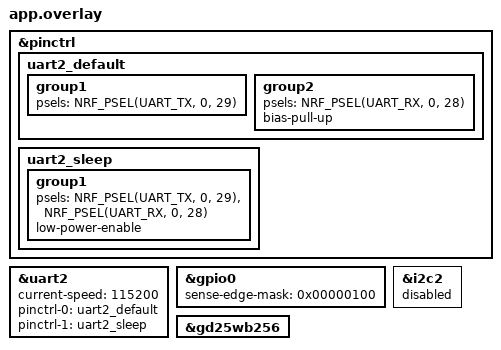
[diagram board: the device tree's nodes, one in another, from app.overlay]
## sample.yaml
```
# Copyright (c) 2026 Nordic Semiconductor ASA
# SPDX-License-Identifier: LicenseRef-Nordic-5-Clause


sample:
  name: nRF Cloud MQTT Device message
tests:
  sample.cellular.nrf_cloud_mqtt_device_message:
    sysbuild: true
    build_only: true
    integration_platforms:
      - nrf9151dk/nrf9151/ns
      - nrf9160dk/nrf9160/ns
      - nrf9161dk/nrf9161/ns
      - thingy91x/nrf9151/ns
    platform_allow:
      - nrf9151dk/nrf9151/ns
      - nrf9160dk/nrf9160/ns
      - nrf9161dk/nrf9161/ns
      - thingy91x/nrf9151/ns
    tags:
      - ci_build
      - sysbuild
      - ci_samples_cellular
```

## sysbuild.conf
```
# Copyright (c) 2026 Nordic Semiconductor ASA
# SPDX-License-Identifier: LicenseRef-Nordic-5-Clause

SB_CONFIG_PARTITION_MANAGER=y
```

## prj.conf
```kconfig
# Copyright (c) 2025 Nordic Semiconductor ASA
#
# SPDX-License-Identifier: LicenseRef-Nordic-5-Clause
#
CONFIG_TFM_PROFILE_TYPE_MINIMAL=y

# Sample
CONFIG_NRF_CLOUD_MQTT_DEVICE_MESSAGE_SAMPLE_LOG_LEVEL_INF=y

# nRF Cloud MQTT
CONFIG_NRF_CLOUD=y
CONFIG_NRF_CLOUD_MQTT=y
CONFIG_NRF_CLOUD_CHECK_CREDENTIALS=y
CONFIG_NRF_CLOUD_CLIENT_ID_SRC_INTERNAL_UUID=y

# MQTT
CONFIG_MQTT_KEEPALIVE=120

# LTE link control
CONFIG_LTE_LINK_CONTROL=y
CONFIG_LTE_LC_PSM_MODULE=y
CONFIG_LTE_LC_EDRX_MODULE=y
# Minimize cloud->device (c2d) downlink latency: do not request PSM or eDRX so
# the modem stays reachable on the shortest paging cycle instead of sleeping.
# Latency-vs-power tradeoff; suitable for a mains-powered gateway.
CONFIG_LTE_PSM_REQ=n
CONFIG_LTE_EDRX_REQ=n

# LEDS and buttons
CONFIG_LED=y
CONFIG_LED_GPIO=y
CONFIG_DK_LIBRARY=y

# Networking
CONFIG_NETWORKING=y
CONFIG_NET_SOCKETS=y
CONFIG_NET_SOCKETS_OFFLOAD=y

# Enable LTE Connectivity using Connection Manager
CONFIG_NET_IPV4=y
CONFIG_NET_IPV6=y
CONFIG_NET_IPV6_NBR_CACHE=n
CONFIG_NET_IPV6_MLD=n
CONFIG_NET_CONNECTION_MANAGER=y
CONFIG_NRF_MODEM_LIB=y
CONFIG_NRF_MODEM_LIB_NET_IF=y
CONFIG_NRF_MODEM_LIB_NET_IF_AUTO_DOWN=y
CONFIG_NRF_MODEM_LIB_NET_IF_DOWN_DEFAULT_LTE_DISCONNECT=y
CONFIG_NET_CONNECTION_MANAGER_MONITOR_STACK_SIZE=1024
CONFIG_NET_MGMT_EVENT_STACK_SIZE=1024


# LTE link control
CONFIG_LTE_LINK_CONTROL=y

# System
CONFIG_HEAP_MEM_POOL_SIZE=19000
CONFIG_MAIN_STACK_SIZE=3072
# 2048 overflowed: the UART->cloud relay work runs here and its
# sscanf/cJSON/nrf_cloud_send(TLS) call tree is deep (crash seen during a full
# "cdb" dump relay). 4096 gives the deep path real headroom.
CONFIG_SYSTEM_WORKQUEUE_STACK_SIZE=4096
CONFIG_ASSERT=n
CONFIG_REBOOT=y
CONFIG_FPU=y
CONFIG_PICOLIBC_IO_FLOAT=y
CONFIG_EVENTS=y
CONFIG_POSIX_API=y

# Logging
CONFIG_LOG=y
CONFIG_LOG_MODE_DEFERRED=y
CONFIG_UART_INTERRUPT_DRIVEN=y
CONFIG_LOG_DEFAULT_LEVEL=3



# Needed for time-stamping messages
CONFIG_DATE_TIME=y
CONFIG_DATE_TIME_NTP=y
CONFIG_PRINTK=y

# AT Host
CONFIG_AT_HOST_LIBRARY=y
CONFIG_AT_MONITOR_HEAP_SIZE=4096
CONFIG_AT_HOST_STACK_SIZE=2048

# Enable settings storage
CONFIG_SETTINGS=y
CONFIG_SETTINGS_FCB=y
CONFIG_FCB=y
CONFIG_FLASH_MAP=y
CONFIG_FLASH=y
CONFIG_FLASH_PAGE_LAYOUT=y

# Modem info
CONFIG_MODEM_INFO=y
CONFIG_MODEM_INFO_ADD_DEVICE=n
CONFIG_MODEM_INFO_ADD_NETWORK=n
CONFIG_MODEM_INFO_ADD_SIM=n

# Modem key management
CONFIG_MODEM_KEY_MGMT=y
CONFIG_NRF_CLOUD_SEC_TAG=16842753

CONFIG_MODEM_JWT=y
CONFIG_NRF_CLOUD_CLIENT_ID_SRC_INTERNAL_UUID=y

# uart
CONFIG_SERIAL=y


# this need to be chcked
CONFIG_TFM_LOG_LEVEL_SILENCE=y
```

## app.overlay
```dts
/*
 * Copyright (c) 2024 Nordic Semiconductor ASA
 *
 * SPDX-License-Identifier: LicenseRef-Nordic-5-Clause
 */

&pinctrl {
	/* configure uart pins
	 * 2-wire link to the nRF54L15 (TX/RX only). RTS/CTS are intentionally
	 * NOT routed: the boards are connected with only two jumpers, so enabling
	 * hardware flow control would leave CTS floating/pulled-high ("not clear
	 * to send") and block all TX. Keep this in sync with the 54 overlay.
	 */
	uart2_default: uart2_default {
		group1 {
			psels = <NRF_PSEL(UART_TX, 0, 29)>; // P0.29 for TX
		};

		group2 {
			psels = <NRF_PSEL(UART_RX, 0, 28)>; // P0.28 for RX
			bias-pull-up;
		};
	};

	uart2_sleep: uart2_sleep {
		/* configure uart pins for sleep mode */
		group1 {
			psels = <NRF_PSEL(UART_TX, 0, 29)>,
				<NRF_PSEL(UART_RX, 0, 28)>;
			low-power-enable;
		};
	};
};

/* 2-wire UART to the nRF54L15 gateway (no hardware flow control) */
&uart2 {
	status = "okay";
	current-speed = <115200>;
	pinctrl-0 = <&uart2_default>;
	pinctrl-1 = <&uart2_sleep>;
	pinctrl-names = "default", "sleep";
};

&gpio0 {
	status = "okay";
	/* Use PORT event for DTR (8) pin to save power */
	sense-edge-mask = <0x00000100>;
};

/* Disable I2C2.
 * - Enabling IO expander causes ~20uA to be consumed while DTR is deasserted.
 * - We use P0.31 and P0.30 pins for DTR and RI signals with external MCU.
 */
&i2c2 {
	status = "disabled";
};

/* Enable external flash */
&gd25wb256 {
	status = "okay";
};
```

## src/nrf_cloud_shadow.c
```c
/* Copyright (c) 2025 Nordic Semiconductor ASA
 *
 * SPDX-License-Identifier: LicenseRef-Nordic-5-Clause
 */

#include <zephyr/kernel.h>
#include <zephyr/logging/log.h>
#include <zephyr/logging/log_ctrl.h>
#include <net/nrf_cloud_codec.h>
#include <net/nrf_cloud.h>
#include "nrf_cloud_shadow.h"

LOG_MODULE_DECLARE(nrf_cloud_mqtt_device_message,
	CONFIG_NRF_CLOUD_MQTT_DEVICE_MESSAGE_SAMPLE_LOG_LEVEL);

/* Flag to indicate that the accepted shadow data has been received */
static bool accepted_rcvd;

void send_initial_log_level(void)
{
	int err;

	NRF_CLOUD_OBJ_JSON_DEFINE(root_obj);
	NRF_CLOUD_OBJ_JSON_DEFINE(ctrl_obj);

	err = nrf_cloud_obj_init(&root_obj);
	if (err) {
		LOG_ERR("Failed to initialize root object: %d", err);
		goto cleanup;
	}

	err = nrf_cloud_obj_init(&ctrl_obj);
	if (err) {
		LOG_ERR("Failed to initialize config object: %d", err);
		(void)nrf_cloud_obj_free(&root_obj);
		goto cleanup;
	}

	/* Create the config object */
	err = nrf_cloud_obj_num_add(&ctrl_obj, NRF_CLOUD_JSON_KEY_LOG,
		(double)CONFIG_LOG_DEFAULT_LEVEL, false);
	if (err) {
		LOG_ERR("Failed to add reported log level, error: %d", err);
		goto cleanup;
	}

	/* Add the config object to the root object */
	err = nrf_cloud_obj_object_add(&root_obj, NRF_CLOUD_JSON_KEY_CTRL, &ctrl_obj, false);
	if (err) {
		LOG_ERR("Failed to add config object to root object: %d", err);
		goto cleanup;
	}

	/* Send the initial config */
	err = nrf_cloud_obj_shadow_update(&root_obj);
	if (err) {
		LOG_ERR("Failed to send initial config, error: %d", err);
	} else {
		LOG_INF("Initial config sent");
	}
cleanup:
	(void)nrf_cloud_obj_free(&ctrl_obj);
	(void)nrf_cloud_obj_free(&root_obj);
}

void shadow_config_cloud_connected(void)
{
	accepted_rcvd = false;
}

static int shadow_config_delta_process(struct nrf_cloud_obj *const delta_obj)
{
	if (!delta_obj) {
		return -EINVAL;
	}

	if ((delta_obj->type != NRF_CLOUD_OBJ_TYPE_JSON) || !delta_obj->json) {
		/* No state JSON */
		return -ENOMSG;
	}

	/* If there is a pending delta event when the device establishes a cloud connection
	 * it is possible that it will be received before the accepted shadow data.
	 * Do not process a delta event until the accepted shadow data has been received.
	 * This is only a concern for MQTT.
	 */
	if (!accepted_rcvd && IS_ENABLED(CONFIG_NRF_CLOUD_MQTT)) {
		return -EAGAIN;
	}

	int err;

	NRF_CLOUD_OBJ_JSON_DEFINE(cfg_obj);

	/* Get the config object */
	err = nrf_cloud_obj_object_detach(delta_obj, NRF_CLOUD_JSON_KEY_CFG, &cfg_obj);
	if (err == -ENODEV) {
		/* No config in the delta */
		return -ENOMSG;
	}

	if (err == -EBADF) {
		/* Clear incoming config */
		nrf_cloud_obj_free(&cfg_obj);
	}

	/* Add the config object back into the state so the response can be sent */
	if (nrf_cloud_obj_object_add(delta_obj, NRF_CLOUD_JSON_KEY_CFG, &cfg_obj, false)) {
		nrf_cloud_obj_free(&cfg_obj);
		return -ENOMEM;
	}

	return err;
}

static int shadow_config_accepted_process(struct nrf_cloud_obj *const accepted_obj)
{
	if (!accepted_obj) {
		return -EINVAL;
	}

	/* The accepted shadow has been received */
	accepted_rcvd = true;

	if ((accepted_obj->type != NRF_CLOUD_OBJ_TYPE_JSON) || !accepted_obj->json) {
		/* No config JSON */
		return -ENOMSG;
	}

	return 0;
}

/* Handler for nRF Cloud shadow events */
void handle_shadow_event(struct nrf_cloud_obj_shadow_data *const shadow)
{
	if (!shadow) {
		return;
	}

	int err;

	if ((shadow->type == NRF_CLOUD_OBJ_SHADOW_TYPE_DELTA) && shadow->delta) {
		LOG_DBG("Shadow: Delta - version: %d, timestamp: %lld",
			shadow->delta->ver,
			shadow->delta->ts);

		if (shadow->delta->is_err) {
			LOG_ERR("Shadow delta error received");
			return;
		}

		bool accept = true;

		err = shadow_config_delta_process(&shadow->delta->state);
		if (err == -EBADF) {
			LOG_INF("Rejecting shadow delta");
			accept = false;
		} else if (err == -ENOMEM) {
			LOG_ERR("Error handling shadow delta");
			return;
		} else if (err == -EAGAIN) {
			LOG_DBG("Ignoring delta until accepted shadow is received");
			return;
		}

		err = nrf_cloud_obj_shadow_delta_response_encode(&shadow->delta->state, accept);
		if (err) {
			LOG_ERR("Failed to encode shadow response: %d", err);
			return;
		}

		err = nrf_cloud_obj_shadow_update(&shadow->delta->state);
		if (err) {
			LOG_ERR("Failed to send shadow response, error: %d", err);
		}

	} else if ((shadow->type == NRF_CLOUD_OBJ_SHADOW_TYPE_TF) && shadow->transform) {
		if (shadow->transform->is_err) {
			LOG_ERR("Shadow transform error received");
			return;
		}
		LOG_DBG("Shadow: Transform");
		err = shadow_config_accepted_process(&shadow->transform->result.obj);
		if (err) {
			/* Send the config on an error */
			send_initial_log_level();
		}
	}
}
```
